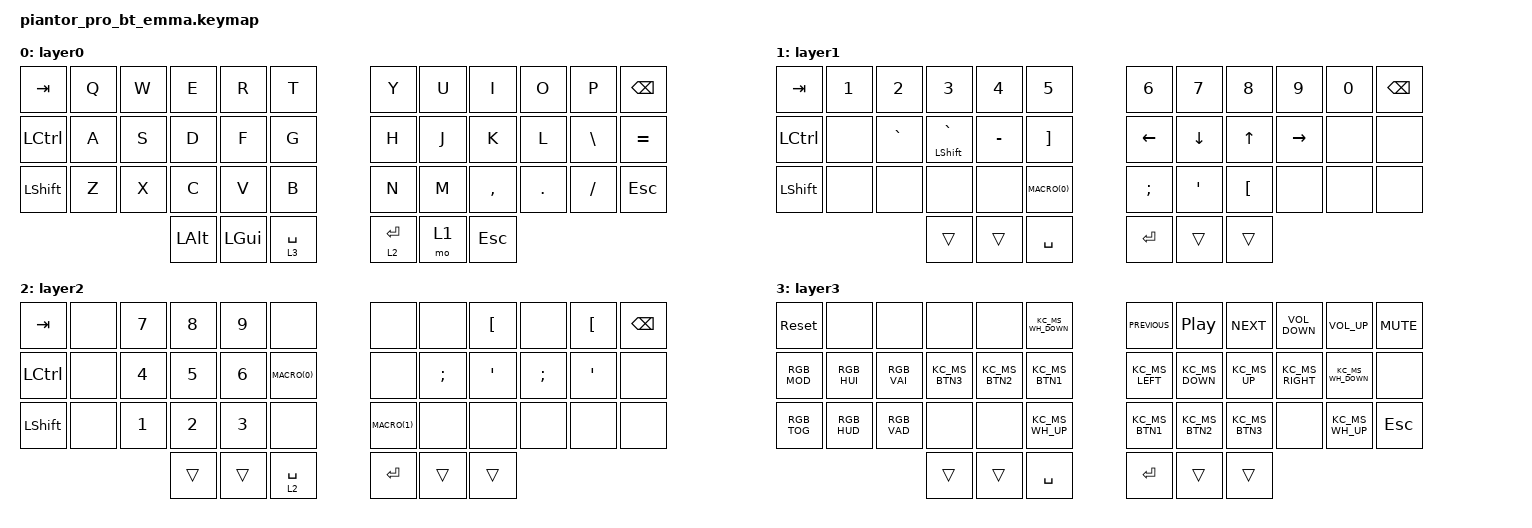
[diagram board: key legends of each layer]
/ {
    macros {
        macro_spotlight: macro_spotlight {
            bindings = <
                &kp LCMD &kp SPACE
            >;
        };
        macro_1: macro_1 {
            // TODO: define your macro here
            bindings = <&none>;
        };
    };
};

// my_macros {
//            compatible = "zmk,behavior-mod-mtap";
//            label = "LGUI_SPC";
//            #binding-cells = <2>;
//            mod = <LGUI>;
//            tap = <SPC>;
//        };

#include <behaviors.dtsi>
#include <dt-bindings/zmk/keys.h>
#include <dt-bindings/zmk/bt.h>
#include <dt-bindings/zmk/rgb.h>

/ {
    chosen {
        zmk,physical-layout = &default_layout;
    };
};

  / {
    keymap {
      compatible = "zmk,keymap";
        layer0 {
          bindings = <
            &kp TAB &kp Q &kp W &kp E &kp R &kp T &kp Y &kp U &kp I &kp O &kp P &kp BACKSPACE 
            &kp LEFT_CONTROL &kp A &kp S &kp D &kp F &kp G &kp H &kp J &kp K &kp L &kp BACKSLASH &kp EQUAL 
            &kp LEFT_SHIFT &kp Z &kp X &kp C &kp V &kp B &kp N &kp M &kp COMMA &kp DOT &kp SLASH &kp ESCAPE 
            &kp LEFT_ALT &kp LEFT_GUI &lt 3 SPACE &lt 2 ENTER &mo 1 &kp ESCAPE
          >;
        };
        layer1 {
          bindings = <
            &kp TAB &kp N1 &kp N2 &kp N3 &kp N4 &kp N5 &kp N6 &kp N7 &kp N8 &kp N9 &kp N0 &kp BACKSPACE 
            &kp LEFT_CONTROL &none &kp GRAVE &mt LEFT_SHIFT GRAVE &kp MINUS &kp RIGHT_BRACKET &kp LEFT &kp DOWN &kp UP &kp RIGHT &none &none 
            &kp LEFT_SHIFT &none &none &none &none [[MACRO(0)]] &kp SEMICOLON &kp SINGLE_QUOTE &kp LEFT_BRACKET &none &none &none 
            &trans &trans &kp SPACE &kp ENTER &trans &trans
          >;
        };
        layer2 {
          bindings = <
            &kp TAB &none &kp N7 &kp N8 &kp N9 &none &none &none &kp LEFT_BRACKET &none &kp LEFT_BRACKET &kp BACKSPACE 
            &kp LEFT_CONTROL &none &kp N4 &kp N5 &kp N6 [[MACRO(0)]] &none &kp SEMICOLON &kp SINGLE_QUOTE &kp SEMICOLON &kp SINGLE_QUOTE &none 
            &kp LEFT_SHIFT &none &kp N1 &kp N2 &kp N3 &none [[MACRO(1)]] &none &none &none &none &none 
            &trans &trans &lt 2 SPACE &kp ENTER &trans &trans
          >;
        };
        layer3 {
          bindings = <
            &sys_reset &none &none &none &none [[KC_MS_WH_DOWN]] &kp C_PREVIOUS &kp C_PLAY_PAUSE &kp C_NEXT &kp C_VOLUME_DOWN &kp C_VOLUME_UP &kp C_MUTE 
            [[RGB_MOD]] [[RGB_HUI]] [[RGB_VAI]] [[KC_MS_BTN3]] [[KC_MS_BTN2]] [[KC_MS_BTN1]] [[KC_MS_LEFT]] [[KC_MS_DOWN]] [[KC_MS_UP]] [[KC_MS_RIGHT]] [[KC_MS_WH_DOWN]] &none [[RGB_TOG]] [[RGB_HUD]] [[RGB_VAD]] &none &none [[KC_MS_WH_UP]] [[KC_MS_BTN1]] [[KC_MS_BTN2]] [[KC_MS_BTN3]] &none [[KC_MS_WH_UP]] &kp ESCAPE &trans &trans &kp SPACE &kp ENTER &trans &trans
          >;
        };
    };
  };
  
